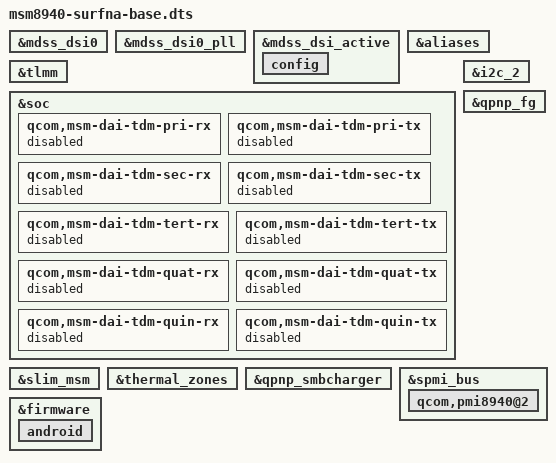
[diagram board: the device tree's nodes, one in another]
/* Copyright (c) 2018, The Linux Foundation. All rights reserved.
 *
 * This program is free software; you can redistribute it and/or modify
 * it under the terms of the GNU General Public License version 2 and
 * only version 2 as published by the Free Software Foundation.
 *
 * This program is distributed in the hope that it will be useful,
 * but WITHOUT ANY WARRANTY; without even the implied warranty of
 * MERCHANTABILITY or FITNESS FOR A PARTICULAR PURPOSE.  See the
 * GNU General Public License for more details.
 */

/dts-v1/;

#include "msm8940-moto-base.dtsi"

&mdss_dsi0 {
	/delete-property/ vdd-supply;
};
&mdss_dsi0_pll {
        /delete-property/ qcom,dsi-pll-ssc-en;
        /delete-property/ qcom,dsi-pll-ssc-mode;
};

&mdss_dsi_active {
	config {
		/delete-property/ output-high;
	};
};

/* fps gpio 8 */
&aliases {
	/delete-property/ spi3;
};

&tlmm {
	/delete-node/ cam_sensor_rear_reset;
	/delete-node/ cam_sensor_rear_reset_sleep;
	/delete-node/ cam_sensor_rear_standby;
	/delete-node/ cam_sensor_rear_standby_sleep;
	/delete-node/ cam_sensor_rear_vdig;
	/delete-node/ cam_sensor_rear_vdig_sleep;
	/delete-node/ cam_sensor_rear_vana;
	/delete-node/ cam_sensor_rear_vana_sleep;
	/delete-node/ cam_sensor_front_default;
	/delete-node/ cam_sensor_front_sleep;
	/delete-node/ cam_sensor_front1_default;
	/delete-node/ cam_sensor_front1_sleep;
	/delete-node/ tlmm_gpio_key;
};

/* camera flash and gpio 50 */
&soc {
	/delete-node/ gpio_keys;
	/delete-node/ spi@78b7000;

	/delete-node/ sound;
	/delete-node/ sound-9335;
	/delete-node/ eldo2;
	/delete-node/ msm_cdc_pinctrl_us_euro_sw;
	/delete-node/ wsa881x_analog_vi_pctrl;
	/delete-node/ wsa881x_analog_clk_pctrl;
	/delete-node/ wsa881x_analog_reset_pctrl;
	/delete-node/ msm_cdc_pinctrl@67;
	/delete-node/ hdmi_dba;
	/delete-node/ dai_hdmi;

	qcom,msm-dai-tdm-pri-rx {
		status = "disabled";
	};
	qcom,msm-dai-tdm-pri-tx {
		status = "disabled";
	};
	qcom,msm-dai-tdm-sec-rx {
		status = "disabled";
	};
	qcom,msm-dai-tdm-sec-tx {
		status = "disabled";
	};
	qcom,msm-dai-tdm-tert-rx {
		status = "disabled";
	};
	qcom,msm-dai-tdm-tert-tx {
		status = "disabled";
	};
	qcom,msm-dai-tdm-quat-rx {
		status = "disabled";
	};
	qcom,msm-dai-tdm-quat-tx {
		status = "disabled";
	};
	qcom,msm-dai-tdm-quin-rx {
		status = "disabled";
	};
	qcom,msm-dai-tdm-quin-tx {
		status = "disabled";
	};
};

&i2c_2 {
	/delete-node/ wsa881x-i2c-codec@f;
	/delete-node/ wsa881x-i2c-codec@45;
	/delete-node/ adv7533@39;
	/delete-node/ pericom-type-c@1d;
};

/*  camera gpio50 and fingerprint spi8 gpio96 */
&slim_msm {
	/delete-node/ tasha_codec;
};

&thermal_zones {
	/delete-node/ quiet-therm-adc;
	/delete-node/ pa-therm1-adc;
	/delete-node/ case-therm-adc;
	/delete-node/ xo-therm-adc;
};

&qpnp_smbcharger {
	/delete-property/ qcom,iterm-ma;
	/delete-property/ qcom,autoadjust-vfloat;
	/delete-property/ qcom,dc-thermal-mitigation;
	/delete-property/ qcom,enable-hvdcp-9v;
};

&qpnp_fg {
	/delete-property/ qcom,ext-sense-type;
	/delete-property/ qcom,support_multi_coefficients;
};

&spmi_bus {
	qcom,pmi8940@2 {
		/delete-node/ qcom,leds@a100;
	};
};

&firmware {
	android {
		/delete-node/ vbmeta;
	};
};
